AUTOSAR XML (schema 4-0-3)
standard types defined: uint8, Boolean, UInt32, UInt8
package /AUTOSAR_Platform/DataConstrs
  range DC_Boolean: raw 0..1
  range DC_UInt8: raw 0..255
package /PATAC/Facility/DataTypes/Implementation
  compu method COMPU_Boolean: 0=FALSE, 1=TRUE
  unit NoUnit: factor-si-to-unit=1, offset-si-to-unit=0
package /PATAC/MSM/ComponentTypes
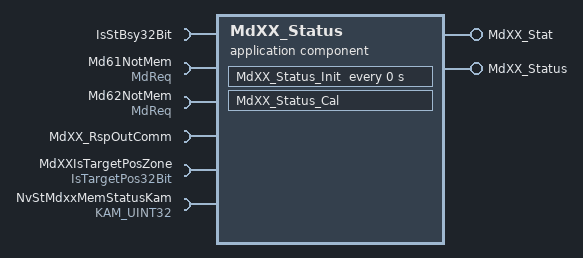
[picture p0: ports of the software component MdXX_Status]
  application sw component type MdXX_Status
    provide port MdXX_Stat: provided-interface=MdXX_Stat
      provided-com-specs:
        data-element=Md1_Stat, init-value=0
        data-element=Md{10..19}_Stat, init-value=0
        data-element=Md2_Stat, init-value=0
        data-element=Md{20..29}_Stat, init-value=0
        data-element=Md3_Stat, init-value=0
        data-element=Md{30..32}_Stat, init-value=0
        data-element=Md{4..9}_Stat, init-value=0
    provide port MdXX_Status: server-com-spec{operation=Cal, queue-length=1}, provided-interface=MdXX_Status
    6 x require port:
      IsStBsy32Bit: nonqueued-receiver-com-spec{data-element=IsStBsy32Bit/Val, filter=data-filter-type=ALWAYS, init-value=0}, required-interface=IsStBsy32Bit
      Md61NotMem: nonqueued-receiver-com-spec{data-element=MdReq/Val, filter=data-filter-type=ALWAYS, init-value=0}, required-interface=MdReq
      Md62NotMem: nonqueued-receiver-com-spec{data-element=MdReq/Val, filter=data-filter-type=ALWAYS, init-value=0}, required-interface=MdReq
      MdXX_RspOutComm: required-interface=MdXX_RspOutComm
        required-com-specs:
          data-element=Md1_RspOutComm, filter=data-filter-type=ALWAYS, init-value=0
          data-element=Md{10..19}_RspOutComm, filter=data-filter-type=ALWAYS, init-value=0
          data-element=Md2_RspOutComm, filter=data-filter-type=ALWAYS, init-value=0
          data-element=Md{20..29}_RspOutComm, filter=data-filter-type=ALWAYS, init-value=0
          data-element=Md3_RspOutComm, filter=data-filter-type=ALWAYS, init-value=0
          data-element=Md{30..32}_RspOutComm, filter=data-filter-type=ALWAYS, init-value=0
          data-element=Md{4..9}_RspOutComm, filter=data-filter-type=ALWAYS, init-value=0
      MdXXIsTargetPosZone: nonqueued-receiver-com-spec{data-element=IsTargetPos32Bit/Val, filter=data-filter-type=ALWAYS, init-value=0}, required-interface=IsTargetPos32Bit
      NvStMdxxMemStatusKam: required-com-specs=[Get, Set], required-interface=KAM_UINT32
    behavior MdXX_Status_InternalBehavior
      operation invoked event OIT_MdXX_Status_Cal_MdXX_Status_Cal: start-on-event=MdXX_Status_Cal, operation=MdXX_Status.Cal
      timing event MdXX_Status_InitEvent: start-on-event=MdXX_Status_Init, period=0
      runnable MdXX_Status_Cal
        data-receive-point-by-arguments:
          36 x access:
            REC_IsStBsy32Bit_Val: accessed-variable=IsStBsy32Bit.Val
            REC_Md61NotMem_Val: accessed-variable=Md61NotMem.Val
            REC_Md62NotMem_Val: accessed-variable=Md62NotMem.Val
            REC_MdXX_RspOutComm_Md1_RspOutComm: accessed-variable=MdXX_RspOutComm.Md1_RspOutComm
            REC_MdXX_RspOutComm_Md{10..19}_RspOutComm: accessed-variable=MdXX_RspOutComm.Md{10..19}_RspOutComm
            REC_MdXX_RspOutComm_Md2_RspOutComm: accessed-variable=MdXX_RspOutComm.Md2_RspOutComm
            REC_MdXX_RspOutComm_Md{20..29}_RspOutComm: accessed-variable=MdXX_RspOutComm.Md{20..29}_RspOutComm
            REC_MdXX_RspOutComm_Md3_RspOutComm: accessed-variable=MdXX_RspOutComm.Md3_RspOutComm
            REC_MdXX_RspOutComm_Md{30..32}_RspOutComm: accessed-variable=MdXX_RspOutComm.Md{30..32}_RspOutComm
            REC_MdXX_RspOutComm_Md{4..9}_RspOutComm: accessed-variable=MdXX_RspOutComm.Md{4..9}_RspOutComm
            REC_MdXXIsTargetPosZone_Val: accessed-variable=MdXXIsTargetPosZone.Val
        data-send-points:
          32 x access:
            SEND_MdXX_Stat_Md1_Stat: accessed-variable=MdXX_Stat.Md1_Stat
            SEND_MdXX_Stat_Md{10..19}_Stat: accessed-variable=MdXX_Stat.Md{10..19}_Stat
            SEND_MdXX_Stat_Md2_Stat: accessed-variable=MdXX_Stat.Md2_Stat
            SEND_MdXX_Stat_Md{20..29}_Stat: accessed-variable=MdXX_Stat.Md{20..29}_Stat
            SEND_MdXX_Stat_Md3_Stat: accessed-variable=MdXX_Stat.Md3_Stat
            SEND_MdXX_Stat_Md{30..32}_Stat: accessed-variable=MdXX_Stat.Md{30..32}_Stat
            SEND_MdXX_Stat_Md{4..9}_Stat: accessed-variable=MdXX_Stat.Md{4..9}_Stat
        sync call SC_NvStMdxxMemStatusKam_Get: operation=NvStMdxxMemStatusKam.Get, timeout=0
        sync call SC_NvStMdxxMemStatusKam_Set: operation=NvStMdxxMemStatusKam.Set, timeout=0
      runnable MdXX_Status_Init
  swc implementation MdXX_Status_Implementation: behavior=MdXX_Status_InternalBehavior
    code-descriptors:
      code Default: artifact-descriptors=autosar-engineering-object={short-label=Default, category=SWSRC}
package /PATAC/MSM/ModeAdjust/PortInterface
  client server interface MdXX_Status
    operation Cal
  5 x sender receiver interface:
    IsStBsy32Bit: invalidation-policy{data-element=IsStBsy32Bit/Val, handle-invalid=DONT-INVALIDATE}
      data Val: type=UInt32
    IsTargetPos32Bit: invalidation-policy{data-element=IsTargetPos32Bit/Val, handle-invalid=DONT-INVALIDATE}
      data Val: type=UInt32
    MdReq: invalidation-policy{data-element=MdReq/Val, handle-invalid=DONT-INVALIDATE}
      data Val: type=Boolean
    MdXX_RspOutComm
      32 x data, all with type=UInt8:
        Md1_RspOutComm
        Md{10..19}_RspOutComm
        Md2_RspOutComm
        Md{20..29}_RspOutComm
        Md3_RspOutComm
        Md{30..32}_RspOutComm
        Md{4..9}_RspOutComm
      invalidation-policys:
        data-element=Md1_RspOutComm, handle-invalid=DONT-INVALIDATE
        data-element=Md{10..19}_RspOutComm, handle-invalid=DONT-INVALIDATE
        data-element=Md2_RspOutComm, handle-invalid=DONT-INVALIDATE
        data-element=Md{20..29}_RspOutComm, handle-invalid=DONT-INVALIDATE
        data-element=Md3_RspOutComm, handle-invalid=DONT-INVALIDATE
        data-element=Md{30..32}_RspOutComm, handle-invalid=DONT-INVALIDATE
        data-element=Md{4..9}_RspOutComm, handle-invalid=DONT-INVALIDATE
    MdXX_Stat
      32 x data, all with type=UInt8:
        Md1_Stat
        Md{10..19}_Stat
        Md2_Stat
        Md{20..29}_Stat
        Md3_Stat
        Md{30..32}_Stat
        Md{4..9}_Stat
      invalidation-policys:
        data-element=Md1_Stat, handle-invalid=DONT-INVALIDATE
        data-element=Md{10..19}_Stat, handle-invalid=DONT-INVALIDATE
        data-element=Md2_Stat, handle-invalid=DONT-INVALIDATE
        data-element=Md{20..29}_Stat, handle-invalid=DONT-INVALIDATE
        data-element=Md3_Stat, handle-invalid=DONT-INVALIDATE
        data-element=Md{30..32}_Stat, handle-invalid=DONT-INVALIDATE
        data-element=Md{4..9}_Stat, handle-invalid=DONT-INVALIDATE
package /PortInterfaces
  client server interface KAM_UINT32
    operation Get
      arg data: type=UInt32, direction=OUT, server-argument-impl-policy=USE-ARGUMENT-TYPE
    operation Set
      arg data: type=UInt32, direction=IN, server-argument-impl-policy=USE-ARGUMENT-TYPE
